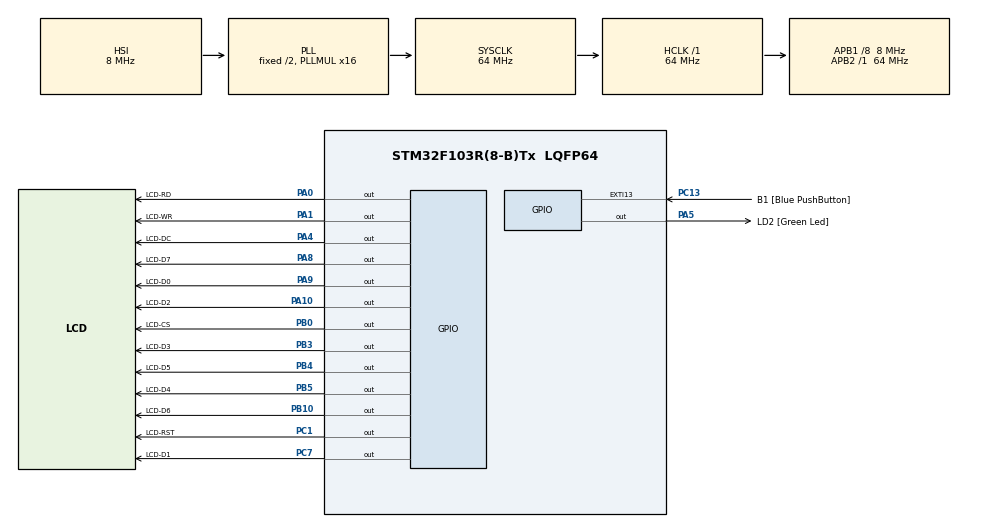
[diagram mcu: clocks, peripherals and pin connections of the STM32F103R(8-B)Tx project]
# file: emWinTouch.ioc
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Mcu.Family=STM32F1
Mcu.Name=STM32F103R(8-B)Tx
Mcu.Package=LQFP64
NVIC.EXTI15_10_IRQn=true\:0\:0\:false\:false\:true
NVIC.PriorityGroup=NVIC_PRIORITYGROUP_4
NVIC.TIM3_IRQn=true\:0\:0\:false\:false\:true
PA0-WKUP.GPIO_Label=LCD-RD
PA0-WKUP.PinState=GPIO_PIN_SET
PA0-WKUP.Signal=GPIO_Output
PA1.GPIO_Label=LCD-WR
PA1.Signal=GPIO_Output
PA10.GPIO_Label=LCD-D2
PA10.Signal=GPIO_Output
PA13.GPIO_Label=TMS
PA13.Mode=Serial_Wire
PA13.Signal=SYS_JTMS-SWDIO
PA14.GPIO_Label=TCK
PA14.Mode=Serial_Wire
PA14.Signal=SYS_JTCK-SWCLK
PA2.GPIO_Label=USART_TX
PA2.GPIO_Mode=GPIO_MODE_AF_PP
PA2.GPIO_PuPd=GPIO_NOPULL
PA2.GPIO_Speed=GPIO_SPEED_FREQ_LOW
PA2.Signal=USART2_TX
PA3.GPIO_Label=USART_RX
PA3.GPIO_Mode=GPIO_MODE_AF_PP
PA3.GPIO_PuPd=GPIO_NOPULL
PA3.GPIO_Speed=GPIO_SPEED_FREQ_LOW
PA3.Signal=USART2_RX
PA4.GPIO_Label=LCD-DC
PA4.Signal=GPIO_Output
PA5.GPIO_Label=LD2 [Green Led]
PA5.GPIO_ModeDefaultOutputPP=GPIO_MODE_OUTPUT_PP
PA5.GPIO_PuPd=GPIO_NOPULL
PA5.GPIO_Speed=GPIO_SPEED_FREQ_LOW
PA5.Signal=GPIO_Output
PA8.GPIO_Label=LCD-D7
PA8.Signal=GPIO_Output
PA9.GPIO_Label=LCD-D0
PA9.Signal=GPIO_Output
PB0.GPIO_Label=LCD-CS
PB0.Signal=GPIO_Output
PB10.GPIO_Label=LCD-D6
PB10.Signal=GPIO_Output
PB3.GPIO_Label=LCD-D3
PB3.Signal=GPIO_Output
PB4.GPIO_Label=LCD-D5
PB4.Signal=GPIO_Output
PB5.GPIO_Label=LCD-D4
PB5.Signal=GPIO_Output
PC1.GPIO_Label=LCD-RST
PC1.PinState=GPIO_PIN_SET
PC1.Signal=GPIO_Output
PC13-TAMPER-RTC.GPIO_Label=B1 [Blue PushButton]
PC13-TAMPER-RTC.GPIO_ModeDefaultEXTI=GPIO_MODE_IT_FALLING
PC13-TAMPER-RTC.GPIO_PuPd=GPIO_NOPULL
PC13-TAMPER-RTC.Signal=GPXTI13
PC14-OSC32_IN.Signal=RCC_OSC32_IN
PC15-OSC32_OUT.Signal=RCC_OSC32_OUT
PC7.GPIO_Label=LCD-D1
PC7.Signal=GPIO_Output
PD0-OSC_IN.Signal=RCC_OSC_IN
PD1-OSC_OUT.Signal=RCC_OSC_OUT
ProjectManager.HeapSize=0x200
ProjectManager.StackSize=0x400
ProjectManager.TargetToolchain=SW4STM32
RCC.AHBFreq_Value=64000000
RCC.APB1CLKDivider=RCC_HCLK_DIV8
RCC.APB1Freq_Value=8000000
RCC.APB1TimFreq_Value=16000000
RCC.APB2Freq_Value=64000000
RCC.APB2TimFreq_Value=64000000
RCC.HCLKFreq_Value=64000000
RCC.PLLMUL=RCC_PLL_MUL16
RCC.SYSCLKFreq_VALUE=64000000
RCC.SYSCLKSource=RCC_SYSCLKSOURCE_PLLCLK
RCC.USBFreq_Value=64000000
TIM3.Period=399
TIM3.Prescaler=3999
VP_TIM3_VS_ClockSourceINT.Mode=Internal
board=NUCLEO-F103RB

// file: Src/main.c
/**
  ******************************************************************************
  * File Name          : main.c
  * Description        : Main program body
  ******************************************************************************
  ** This notice applies to any and all portions of this file
  * that are not between comment pairs USER CODE BEGIN and
  * USER CODE END. Other portions of this file, whether
  * inserted by the user or by software development tools
  * are owned by their respective copyright owners.
  *
  * COPYRIGHT(c) 2018 STMicroelectronics
  *
  * Redistribution and use in source and binary forms, with or without modification,
  * are permitted provided that the following conditions are met:
  *   1. Redistributions of source code must retain the above copyright notice,
  *      this list of conditions and the following disclaimer.
  *   2. Redistributions in binary form must reproduce the above copyright notice,
  *      this list of conditions and the following disclaimer in the documentation
  *      and/or other materials provided with the distribution.
  *   3. Neither the name of STMicroelectronics nor the names of its contributors
  *      may be used to endorse or promote products derived from this software
  *      without specific prior written permission.
  *
  * THIS SOFTWARE IS PROVIDED BY THE COPYRIGHT HOLDERS AND CONTRIBUTORS "AS IS"
  * AND ANY EXPRESS OR IMPLIED WARRANTIES, INCLUDING, BUT NOT LIMITED TO, THE
  * IMPLIED WARRANTIES OF MERCHANTABILITY AND FITNESS FOR A PARTICULAR PURPOSE ARE
  * DISCLAIMED. IN NO EVENT SHALL THE COPYRIGHT HOLDER OR CONTRIBUTORS BE LIABLE
  * FOR ANY DIRECT, INDIRECT, INCIDENTAL, SPECIAL, EXEMPLARY, OR CONSEQUENTIAL
  * DAMAGES (INCLUDING, BUT NOT LIMITED TO, PROCUREMENT OF SUBSTITUTE GOODS OR
  * SERVICES; LOSS OF USE, DATA, OR PROFITS; OR BUSINESS INTERRUPTION) HOWEVER
  * CAUSED AND ON ANY THEORY OF LIABILITY, WHETHER IN CONTRACT, STRICT LIABILITY,
  * OR TORT (INCLUDING NEGLIGENCE OR OTHERWISE) ARISING IN ANY WAY OUT OF THE USE
  * OF THIS SOFTWARE, EVEN IF ADVISED OF THE POSSIBILITY OF SUCH DAMAGE.
  *
  ******************************************************************************
  */
#include "main.h"
#include "stm32f1xx_hal.h"

TIM_HandleTypeDef htim3;

/* USER CODE BEGIN PV */
/* Private variables ---------------------------------------------------------*/

/* USER CODE END PV */

void SystemClock_Config(void);
static void MX_GPIO_Init(void);
static void MX_TIM3_Init(void);

/* USER CODE BEGIN PFP */
/* Private function prototypes -----------------------------------------------*/
//extern void initialise_monitor_handles(void); //Linker-Miscellaneous-flags: -specs=rdimon.specs -lc -lrdimon
/* USER CODE END PFP */

int main(void)
{

  /* USER CODE BEGIN 1 */
/*	initialise_monitor_handles();
	printf("Hello\n");*/
  /* USER CODE END 1 */

  /* MCU Configuration----------------------------------------------------------*/

  /* Reset of all peripherals, Initializes the Flash interface and the Systick. */
  HAL_Init();

  /* Configure the system clock */
  SystemClock_Config();

  /* Initialize all configured peripherals */
  MX_GPIO_Init();
  MX_TIM3_Init();

  /* USER CODE BEGIN 2 */

  __HAL_RCC_CRC_CLK_ENABLE();

	MainTask();

  /* USER CODE END 2 */

  /* Infinite loop */
  while (1)
  {

  }

}

/** System Clock Configuration
*/
void SystemClock_Config(void)
{

  RCC_OscInitTypeDef RCC_OscInitStruct;
  RCC_ClkInitTypeDef RCC_ClkInitStruct;
  RCC_PeriphCLKInitTypeDef PeriphClkInit;

    /**Initializes the CPU, AHB and APB busses clocks
    */
  RCC_OscInitStruct.OscillatorType = RCC_OSCILLATORTYPE_HSI;
  RCC_OscInitStruct.HSIState = RCC_HSI_ON;
  RCC_OscInitStruct.HSICalibrationValue = 16;
  RCC_OscInitStruct.PLL.PLLState = RCC_PLL_ON;
  RCC_OscInitStruct.PLL.PLLSource = RCC_PLLSOURCE_HSI_DIV2;
  RCC_OscInitStruct.PLL.PLLMUL = RCC_PLL_MUL16;
  if (HAL_RCC_OscConfig(&RCC_OscInitStruct) != HAL_OK)
  {
    _Error_Handler(__FILE__, __LINE__);
  }

    /**Initializes the CPU, AHB and APB busses clocks
    */
  RCC_ClkInitStruct.ClockType = RCC_CLOCKTYPE_HCLK|RCC_CLOCKTYPE_SYSCLK
                              |RCC_CLOCKTYPE_PCLK1|RCC_CLOCKTYPE_PCLK2;
  RCC_ClkInitStruct.SYSCLKSource = RCC_SYSCLKSOURCE_PLLCLK;
  RCC_ClkInitStruct.AHBCLKDivider = RCC_SYSCLK_DIV1;
  RCC_ClkInitStruct.APB1CLKDivider = RCC_HCLK_DIV8;
  RCC_ClkInitStruct.APB2CLKDivider = RCC_HCLK_DIV1;

  if (HAL_RCC_ClockConfig(&RCC_ClkInitStruct, FLASH_LATENCY_2) != HAL_OK)
  {
    _Error_Handler(__FILE__, __LINE__);
  }

  PeriphClkInit.PeriphClockSelection = RCC_PERIPHCLK_ADC;
  PeriphClkInit.AdcClockSelection = RCC_ADCPCLK2_DIV6;
  if (HAL_RCCEx_PeriphCLKConfig(&PeriphClkInit) != HAL_OK)
  {
    _Error_Handler(__FILE__, __LINE__);
  }
    /**Configure the Systick interrupt time
    */
  HAL_SYSTICK_Config(HAL_RCC_GetHCLKFreq()/1000);

    /**Configure the Systick
    */
  HAL_SYSTICK_CLKSourceConfig(SYSTICK_CLKSOURCE_HCLK);

  /* SysTick_IRQn interrupt configuration */
  HAL_NVIC_SetPriority(SysTick_IRQn, 0, 0);
}

/* TIM3 init function */
static void MX_TIM3_Init(void)
{

  TIM_ClockConfigTypeDef sClockSourceConfig;
  TIM_MasterConfigTypeDef sMasterConfig;

  htim3.Instance = TIM3;
  htim3.Init.Prescaler = 1999;
  htim3.Init.CounterMode = TIM_COUNTERMODE_UP;
  htim3.Init.Period = 1999;
  htim3.Init.ClockDivision = TIM_CLOCKDIVISION_DIV2;
  if (HAL_TIM_Base_Init(&htim3) != HAL_OK)
  {
    _Error_Handler(__FILE__, __LINE__);
  }

  sClockSourceConfig.ClockSource = TIM_CLOCKSOURCE_INTERNAL;
  if (HAL_TIM_ConfigClockSource(&htim3, &sClockSourceConfig) != HAL_OK)
  {
    _Error_Handler(__FILE__, __LINE__);
  }

  sMasterConfig.MasterOutputTrigger = TIM_TRGO_RESET;
  sMasterConfig.MasterSlaveMode = TIM_MASTERSLAVEMODE_DISABLE;
  if (HAL_TIMEx_MasterConfigSynchronization(&htim3, &sMasterConfig) != HAL_OK)
  {
    _Error_Handler(__FILE__, __LINE__);
  }

}

/** Configure pins as
        * Analog
        * Input
        * Output
        * EVENT_OUT
        * EXTI
     PA2   ------> USART2_TX
     PA3   ------> USART2_RX
*/
static void MX_GPIO_Init(void)
{

  GPIO_InitTypeDef GPIO_InitStruct;

  /* GPIO Ports Clock Enable */
  __HAL_RCC_GPIOC_CLK_ENABLE();
  __HAL_RCC_GPIOD_CLK_ENABLE();
  __HAL_RCC_GPIOA_CLK_ENABLE();
  __HAL_RCC_GPIOB_CLK_ENABLE();

  /*Configure GPIO pin Output Level */
  HAL_GPIO_WritePin(LCD_RST_GPIO_Port, LCD_RST_Pin, GPIO_PIN_SET);

  /*Configure GPIO pin Output Level */
  HAL_GPIO_WritePin(LCD_RD_GPIO_Port, LCD_RD_Pin, GPIO_PIN_SET);

  /*Configure GPIO pin Output Level */
  HAL_GPIO_WritePin(GPIOA, LCD_WR_Pin|LCD_DC_Pin|LD2_Pin|LCD_D7_Pin
                          |LCD_D0_Pin|LCD_D2_Pin, GPIO_PIN_RESET);

  /*Configure GPIO pin Output Level */
  HAL_GPIO_WritePin(GPIOB, LCD_CS_Pin|LCD_D6_Pin|LCD_D3_Pin|LCD_D5_Pin
                          |LCD_D4_Pin, GPIO_PIN_RESET);

  /*Configure GPIO pin Output Level */
  HAL_GPIO_WritePin(LCD_D1_GPIO_Port, LCD_D1_Pin, GPIO_PIN_RESET);

  /*Configure GPIO pin : B1_Pin */
  GPIO_InitStruct.Pin = B1_Pin;
  GPIO_InitStruct.Mode = GPIO_MODE_IT_FALLING;
  GPIO_InitStruct.Pull = GPIO_NOPULL;
  HAL_GPIO_Init(B1_GPIO_Port, &GPIO_InitStruct);

  /*Configure GPIO pins : LCD_RST_Pin LCD_D1_Pin */
  GPIO_InitStruct.Pin = LCD_RST_Pin|LCD_D1_Pin;
  GPIO_InitStruct.Mode = GPIO_MODE_OUTPUT_PP;
  GPIO_InitStruct.Speed = GPIO_SPEED_FREQ_LOW;
  HAL_GPIO_Init(GPIOC, &GPIO_InitStruct);

  /*Configure GPIO pins : LCD_RD_Pin LCD_WR_Pin LCD_DC_Pin LD2_Pin
                           LCD_D7_Pin LCD_D0_Pin LCD_D2_Pin */
  GPIO_InitStruct.Pin = LCD_RD_Pin|LCD_WR_Pin|LCD_DC_Pin|LD2_Pin
                          |LCD_D7_Pin|LCD_D0_Pin|LCD_D2_Pin;
  GPIO_InitStruct.Mode = GPIO_MODE_OUTPUT_PP;
  GPIO_InitStruct.Speed = GPIO_SPEED_FREQ_LOW;
  HAL_GPIO_Init(GPIOA, &GPIO_InitStruct);

  /*Configure GPIO pins : USART_TX_Pin USART_RX_Pin */
  GPIO_InitStruct.Pin = USART_TX_Pin|USART_RX_Pin;
  GPIO_InitStruct.Mode = GPIO_MODE_AF_PP;
  GPIO_InitStruct.Speed = GPIO_SPEED_FREQ_LOW;
  HAL_GPIO_Init(GPIOA, &GPIO_InitStruct);

  /*Configure GPIO pins : LCD_CS_Pin LCD_D6_Pin LCD_D3_Pin LCD_D5_Pin
                           LCD_D4_Pin */
  GPIO_InitStruct.Pin = LCD_CS_Pin|LCD_D6_Pin|LCD_D3_Pin|LCD_D5_Pin
                          |LCD_D4_Pin;
  GPIO_InitStruct.Mode = GPIO_MODE_OUTPUT_PP;
  GPIO_InitStruct.Speed = GPIO_SPEED_FREQ_LOW;
  HAL_GPIO_Init(GPIOB, &GPIO_InitStruct);

  /* EXTI interrupt init*/
  HAL_NVIC_SetPriority(EXTI15_10_IRQn, 0, 0);
  HAL_NVIC_EnableIRQ(EXTI15_10_IRQn);

}

void _Error_Handler(char * file, int line)
{
  while(1)
  {
  }
}

/************************ (C) COPYRIGHT STMicroelectronics *****END OF FILE****/
